# DSP1_MMU0_DSP register map
Vendor: Texas Instruments
Peripheral module from a debugger description file (folder am572x).
Registers are 32-bit, access per field, reset 0x0 unless marked. A register's access mark holds for its fields unless they carry their own. Offsets are as the file gives them; lines under a group give offsets from that group; [hi:lo] are bit positions; {n}, {i} and the like mark numbered series; 'fields as' and 'values as' point back to an identical list; <NAME> marks a mode.

## DSP1_MMU0_DSP
0x00 MMU_REVISION ro reset not defined — This register contains the IP revision code
  [31:0] REVISION — IP Revision
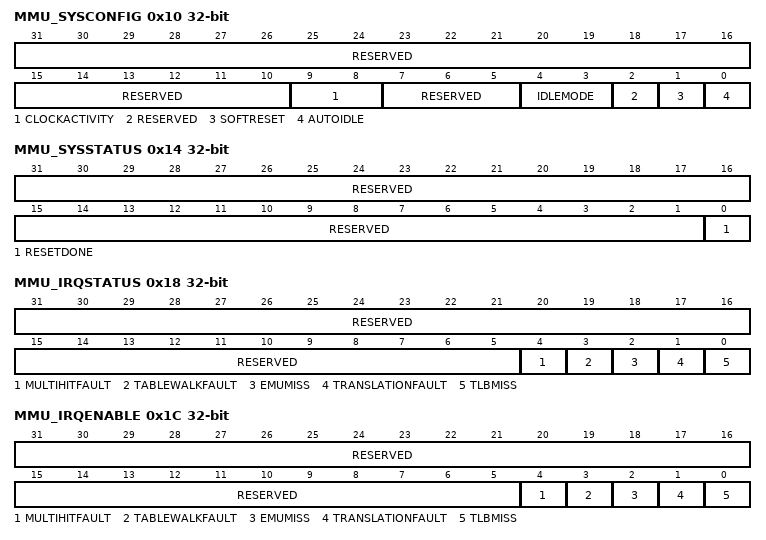
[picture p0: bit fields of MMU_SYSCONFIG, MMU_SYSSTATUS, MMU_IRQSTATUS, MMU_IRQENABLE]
0x10 MMU_SYSCONFIG — This register controls the various parameters of the OCP interface
  [31:10] RESERVED ro — Write 0's for future compatibility. Reads return 0
  [9:8] CLOCKACTIVITY ro — Clock activity during wake-up mode
    0=OCP_0 (Functional and OCP clocks can be switched off)
  [7:5] RESERVED ro — Write 0's for future compatibility Reads returns 0
  [4:3] IDLEMODE rw
    0=SFIDLE (Force-idle. An idle request is acknowledged unconditionally); 1=SNIDLE (No-idle. An idle request is never acknowledged); 2=SSIDLE (Smart-idle. Acknowledgement to an idle request is given based on the internal activity of the module)
  [2] RESERVED ro — Write 0's for future compatibility Reads returns 0
  [1] SOFTRESET wo — Software reset. This bit is automatically reset by the hardware. During reads, it always return 0
    0=NOFUN_W (No functional effect); 1=RSTMODE_W (The module is reset)
  [0] AUTOIDLE rw — Internal OCP clock gating strategy
    0=CLKFREE (OCP clock is free-running); 1=AUTOCLKGATE (Automatic interconnect clock gating strategy is applied, based on the interconnect interface activity)
0x14 MMU_SYSSTATUS ro (reset mask 0xFFFFFFFE) — This register provides status information about the module, excluding the interrupt status information
  [31:1] RESERVED — Reads returns 0
  [0] RESETDONE — Internal reset monitoring
    0=RSTONGOING (Internal module reset in on-going); 1=RSTCOMP (Reset completed)
0x18 MMU_IRQSTATUS access not given — This interrupt status register regroups all the status of the module internal events that can generate an interrupt.
  [31:5] RESERVED ro — Write 0's for future compatibility. Read returns 0
  [4] MULTIHITFAULT — Error due to multiple matches in the TLB (access RW (W1toClr))
    0=NMHF_R (MultiHitFault false); 0=MHFSTAT_W (MultiHitFault status bit unchanged); 1=RMHFSTAT_W (MultiHitFault status bit is reset); 1=MHF_R (MultiHitFault is true ('pending'))
  [3] TABLEWALKFAULT — Error response received during a Table Walk (access RW (W1toClr))
    0=NTWF_R (TableWalkFault false); 0=TWFSTAT_W (TableWalkFault status bit unchanged); 1=RTWFSTAT_W (TableWalkFault status bit is reset); 1=TWF_R (TableWalkFault is true ('pending'))
  [2] EMUMISS — Unrecoverable TLB miss during debug (hardware TWL disabled) (access RW (W1toClr))
    0=NEMUM_R (EMUMiss false); 0=ESTAT_W (EMUMiss status bit unchanged); 1=RESTAT_W (EMUMiss status bit is reset); 1=EMUM_R (EMUMiss is true ('pending'))
  [1] TRANSLATIONFAULT — Invalid descriptor in translation tables (translation fault) (access RW (W1toClr))
    0=NFAULT_R (TranslationFault false); 0=FSTAT_W (TranslationFault status bit unchanged); 1=RFSTAT_W (TranslationFault status bit is reset); 1=FAULT_R (TranslationFault is true ('pending'))
  [0] TLBMISS — Unrecoverable TLB miss (hardware TWL disabled) (access RW (W1toClr))
    0=NTLBM_R (TLBMiss false); 0=MSTAT_W (TLBMiss status bit unchanged); 1=RMSTAT_W (TLBMiss status bit is reset); 1=TLBM_R (TLBMiss is true ('pending'))
0x1C MMU_IRQENABLE — The interrupt enable register allows to mask/unmask the module internal sources of interrupt, on a event-by-event basis.
  [31:5] RESERVED ro — Write 0's for future compatibility Read returns 0
  [4] MULTIHITFAULT rw — Error due to multiple matches in the TLB
    0=MHFLTMASK (MultiHitFault is masked); 1=MHFLTGINT (MultiHitFault event generates an interrupt if occurs)
  [3] TABLEWALKFAULT rw — Error response received during a Table Walk
    0=TWLFLTMASK (TableWalkFault is masked); 1=TWLFLTGINT (TableWalkFault event generates an interrupt if occurs)
  [2] EMUMISS rw — Unrecoverable TLB miss during debug (hardware TWL disabled)
    0=EMUMFLTMASK (EMUMiss interrupt is masked); 1=EMUMFLTGINT (EMUMiss event generates an interrupt when it occurs)
  [1] TRANSLATIONFAULT rw — Invalid descriptor in translation tables (translation fault)
    0=TRANFLTMASK (TranslationFault is masked); 1=TRANFLTGINT (TranslationFault event generates an interrupt if occurs)
  [0] TLBMISS rw — Unrecoverable TLB miss (hardware TWL disabled)
    0=TRMISSINTM (TLBMiss interrupt is masked); 1=TRMISSGINT (TLBMiss event generates an interrupt when if occurs)
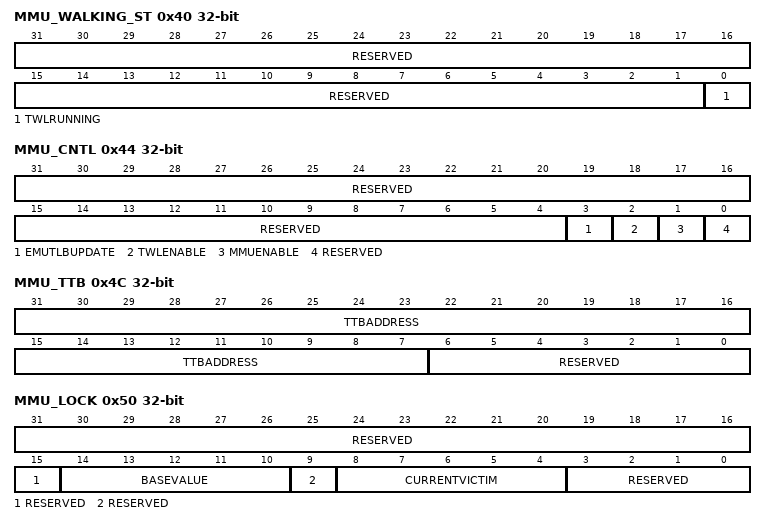
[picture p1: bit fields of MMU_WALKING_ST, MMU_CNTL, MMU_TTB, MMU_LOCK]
0x40 MMU_WALKING_ST ro — This register provides status information about the table walking logic
  [31:1] RESERVED — Reads return 0
  [0] TWLRUNNING — Table Walking Logic is running
    0=TWLCOMP (TWL Completed); 1=TWLRUN (TWL Running)
0x44 MMU_CNTL — This register programs the MMU features
  [31:4] RESERVED ro — Write 0's for future compatibility. Reads return 0
  [3] EMUTLBUPDATE rw — Enable TLB update on emulator table walk
    0=EMUDIS (Emulator TLB update disabled); 1=EMUEN (Emulator TLB update enabled)
  [2] TWLENABLE rw — Table Walking Logic enable
    0=TWLDIS (TWL disabled); 1=TWLEN (TWL enabled)
  [1] MMUENABLE rw
    0=MMUDIS (MMU disabled); 1=MMUEN (MMU enabled)
  [0] RESERVED ro — Write 0's for future compatibility. Reads return 0
0x48 MMU_FAULT_AD ro — This register contains the virtual address that generated the interrupt
  [31:0] FAULTADDRESS — Virtual address of the access that generated a fault
0x4C MMU_TTB — This register contains the Translation Table Base address
  [31:7] TTBADDRESS rw — Translation Table Base Address
  [6:0] RESERVED ro — Write 0's for future compatibility. Reads retiurn 0
0x50 MMU_LOCK — This register locks some of the TLB entries
  [31:15] RESERVED ro — Write 0's for future compatibility. Reads return 0
  [14:10] BASEVALUE rw — Locked entries base value.
  [9] RESERVED ro — Write 0's for future compatibility. Reads return 0
  [8:4] CURRENTVICTIM rw — Current entry to be updated either by the TWL or by the software.
  [3:0] RESERVED ro — Write 0's for future compatibility. Reads return 0
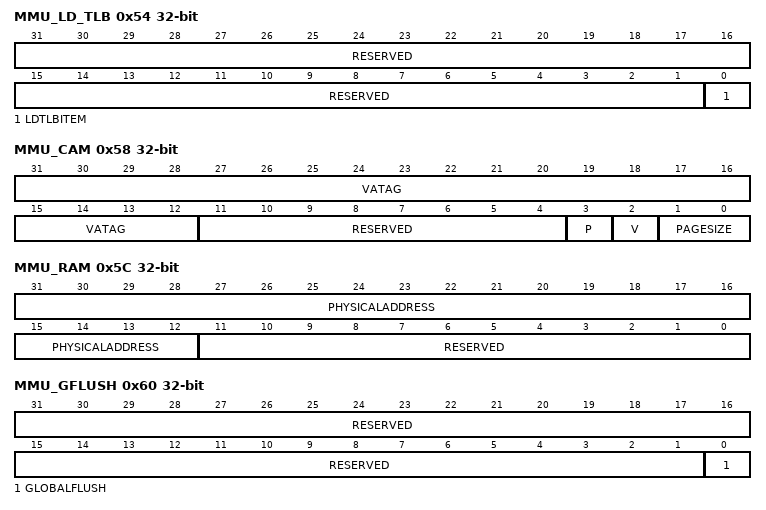
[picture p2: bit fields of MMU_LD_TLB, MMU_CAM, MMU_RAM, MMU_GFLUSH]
0x54 MMU_LD_TLB — This register loads a TLB entry (CAM+RAM)
  [31:1] RESERVED ro — Write 0's for future compatibility. Reads return 0
  [0] LDTLBITEM wo — Write (load) data in the TLB. Reads return 0.
    0=NOEFFECT_W (No functional effect); 1=LDTLB_W (Load TLB data)
0x58 MMU_CAM — This register holds a CAM entry
  [31:12] VATAG rw — Virtual address tag
  [11:4] RESERVED ro — Write 0's for future compatibility. Reads return 0
  [3] P rw — Preserved bit
    0=CANFLUSH (TLB entry may be flushed); 1=NOFLUSH (TLB entry is protected against flush)
  [2] V rw — Valid bit
    0=INVALID (TLB entry is invalid); 1=VALID (TLB entry is valid)
  [1:0] PAGESIZE rw
    0=SECTION (Section (1 MiB)); 1=LARGE (Large page (64 KiB)); 2=SMALL (Small page (4 KiB)); 3=SUPER (Supersection (16 MiB))
0x5C MMU_RAM — This register contains bits [31:12] of the physical address to be written to a TLB entry pointed to by CURRENTVICTIM field of register.
  [31:12] PHYSICALADDRESS rw — Physical address of the page
  [11:0] RESERVED ro — Write 0's for future compatibility. Reads return 0
0x60 MMU_GFLUSH — This register flushes all the non-protected TLB entries
  [31:1] RESERVED ro — Write 0's for future compatibility. Reads return 0
  [0] GLOBALFLUSH wo — Flush all the non-protected TLB entries when set. Reads return 0.
    0=NFT_W (No functional effect); 1=FLUSH_W (Flush all the non-protected TLB entries)
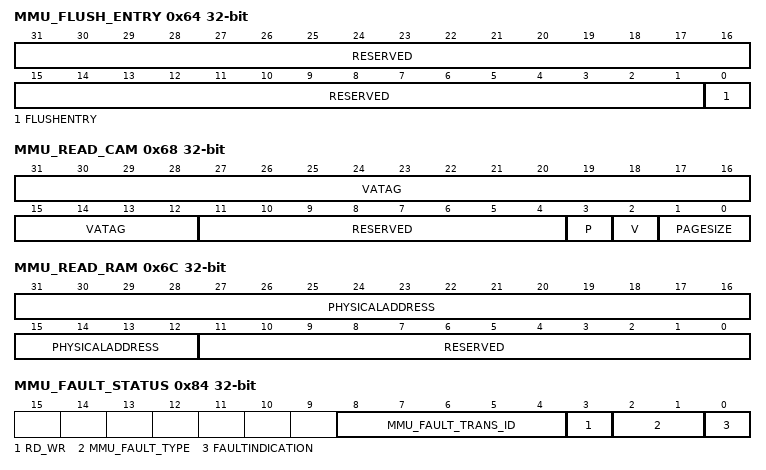
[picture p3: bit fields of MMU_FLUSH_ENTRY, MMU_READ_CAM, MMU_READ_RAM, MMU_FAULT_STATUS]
0x64 MMU_FLUSH_ENTRY — This register flushes the entry pointed to by the CAM virtual address
  [31:1] RESERVED ro — Write 0's for future compatibility. Reads return 0
  [0] FLUSHENTRY wo — Flush the TLB entry pointed by the virtual address (VATag) inMMU_CAM register, even if this entry is set protected. Reads return 0.
    0=NOFUN_W (No functional effect); 1=FLUSHTLB_W (Flush all the TLB entries specified by the CAM register)
0x68 MMU_READ_CAM ro — This register reads CAM data from a CAM entry
  [31:12] VATAG — Virtual address tag
  [11:4] RESERVED — Reads return 0
  [3] P — Preserved bit
    values as MMU_CAM.P
  [2] V — Valid bit
    values as MMU_CAM.V
  [1:0] PAGESIZE
    values as MMU_CAM.PAGESIZE
0x6C MMU_READ_RAM ro — This register reads bits [31:12] of the physical address from the TLB entry pointed to by CURRENTVICTIM field of the register.
  [31:12] PHYSICALADDRESS — Physical address of the page
  [11:0] RESERVED — Reads return 0
0x70 MMU_EMU_FAULT_AD ro — This register contains the last virtual address of a fault caused by the debugger
  [31:0] EMUFAULTADDRESS — Virtual address of the last emulator access that generated a fault
0x80 MMU_FAULT_PC ro — Typically CPU program counter value of instruction generating MMU fault. The address value is captured at [31:0] EMUFAULTADDRESS. Data-Read-access : corresponding PC. Data-write-access : not perfect accuracy due to posted-write.
  [31:0] PC — Typically CPU program counter value of instruction generating MMU fault
0x84 MMU_FAULT_STATUS access not given — Fault status register
  [8:4] MMU_FAULT_TRANS_ID ro — MtagID of the transaction that caused fault
  [3] RD_WR ro — Indicates read or write
    0=WRITE; 1=READ
  [2:1] MMU_FAULT_TYPE ro — MReqInfo[1:0] is captured as fault type
  [0] FAULTINDICATION — Indicates an MMU fault (access RW (W1toClr))
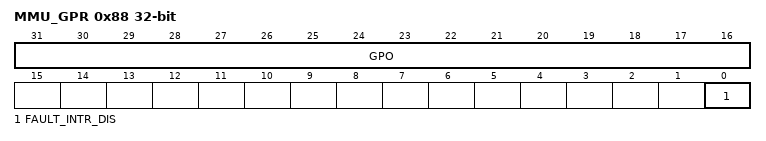
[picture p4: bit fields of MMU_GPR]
0x88 MMU_GPR — General purpose register
  [31:16] GPO rw — General purpose output sent out as MMU output
  [0] FAULT_INTR_DIS rw — Disable generation of interrupt on fault. Error response is returned instead on the slave port
0x90 MMU_BYPASS_REGION1_ADDR — This register contains the start address of the first NO TRANSLATION REGION for 2D bursts
  [31:16] START_ADDR rw — Start address of NO TRANSLATION REGION for 2D bursts. This has to be aligned to SIZE inMMU_BYPASS_REGION1_SIZE
0x94 MMU_BYPASS_REGION1_SIZE — This register contains the size of first NO TRANSLATION REGION for
  [3:0] SIZE rw — Size of the NO TRANSLATION REGION of 2D bursts. 0x0 = region not valid 0x1 = 64K bytes 0x2 = 128K bytes 0x3 = 256K bytes 0x4 = 512K bytes 0x5 = 1M bytes 0x6 = 2M bytes 0x7 = 4M bytes 0x8 = 8M bytes 0x9 = 16M bytes 0xA = 32M bytes 0xB = 64M bytes 0xC = 128M bytes 0xD = 256M bytes 0xE = 512M bytes 0xF = 1G bytes
0x98 MMU_BYPASS_REGION2_ADDR — This register contains the start address of the second NO TRANSLATION REGION for 2D bursts
  [31:16] START_ADDR rw — Start address of NO TRANSLATION REGION for 2D bursts. This has to be aligned to SIZE inMMU_BYPASS_REGION2_SIZE.
0x9C MMU_BYPASS_REGION2_SIZE — This register contains the size of second NO TRANSLATION REGION for 2D bursts
  fields as MMU_BYPASS_REGION1_SIZE
0xA0 MMU_BYPASS_REGION3_ADDR — This register contains the start address of the third NO TRANSLATION REGION for 2D bursts
  fields as MMU_BYPASS_REGION2_ADDR
0xA4 MMU_BYPASS_REGION3_SIZE — This register contains the size of third NO TRANSLATION REGION for 2D bursts
  fields as MMU_BYPASS_REGION1_SIZE
0xA8 MMU_BYPASS_REGION4_ADDR — This register contains the start address of the forth NO TRANSLATION REGION for 2D bursts
  fields as MMU_BYPASS_REGION2_ADDR
0xAC MMU_BYPASS_REGION4_SIZE — This register contains the size of forth NO TRANSLATION REGION for 2D bursts
  fields as MMU_BYPASS_REGION1_SIZE
